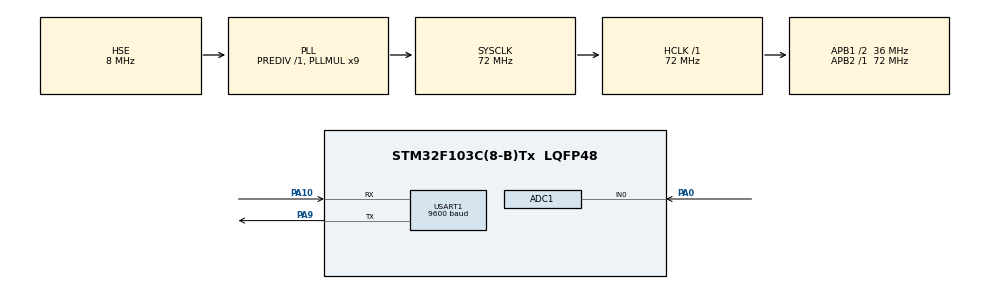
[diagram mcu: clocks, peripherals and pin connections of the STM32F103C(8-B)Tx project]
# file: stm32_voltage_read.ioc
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ADC1.Channel-0\#ChannelRegularConversion=ADC_CHANNEL_0
ADC1.NbrOfConversionFlag=1
ADC1.Rank-0\#ChannelRegularConversion=1
ADC1.SamplingTime-0\#ChannelRegularConversion=ADC_SAMPLETIME_1CYCLE_5
ADC1.master=1
Mcu.Family=STM32F1
Mcu.Name=STM32F103C(8-B)Tx
Mcu.Package=LQFP48
NVIC.PriorityGroup=NVIC_PRIORITYGROUP_4
PA0-WKUP.Signal=ADCx_IN0
PA10.Mode=Asynchronous
PA10.Signal=USART1_RX
PA13.Mode=Serial_Wire
PA13.Signal=SYS_JTMS-SWDIO
PA14.Mode=Serial_Wire
PA14.Signal=SYS_JTCK-SWCLK
PA9.Mode=Asynchronous
PA9.Signal=USART1_TX
PC14-OSC32_IN.Mode=LSE-External-Oscillator
PC14-OSC32_IN.Signal=RCC_OSC32_IN
PC15-OSC32_OUT.Mode=LSE-External-Oscillator
PC15-OSC32_OUT.Signal=RCC_OSC32_OUT
PD0-OSC_IN.Mode=HSE-External-Oscillator
PD0-OSC_IN.Signal=RCC_OSC_IN
PD1-OSC_OUT.Mode=HSE-External-Oscillator
PD1-OSC_OUT.Signal=RCC_OSC_OUT
ProjectManager.HeapSize=0x200
ProjectManager.StackSize=0x400
ProjectManager.TargetToolchain=STM32CubeIDE
RCC.ADCPresc=RCC_ADCPCLK2_DIV6
RCC.AHBFreq_Value=72000000
RCC.APB1CLKDivider=RCC_HCLK_DIV2
RCC.APB1Freq_Value=36000000
RCC.APB1TimFreq_Value=72000000
RCC.APB2Freq_Value=72000000
RCC.APB2TimFreq_Value=72000000
RCC.HCLKFreq_Value=72000000
RCC.PLLMUL=RCC_PLL_MUL9
RCC.PLLSourceVirtual=RCC_PLLSOURCE_HSE
RCC.SYSCLKFreq_VALUE=72000000
RCC.SYSCLKSource=RCC_SYSCLKSOURCE_PLLCLK
RCC.USBFreq_Value=72000000
SH.ADCx_IN0.0=ADC1_IN0,IN0
USART1.BaudRate=9600
USART1.VirtualMode=VM_ASYNC
board=custom

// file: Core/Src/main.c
/* USER CODE BEGIN Header */
/**
  ******************************************************************************
  * @file           : main.c
  * @brief          : Main program body
  ******************************************************************************
  * @attention
  *
  * <h2><center>&copy; Copyright (c) 2021 STMicroelectronics.
  * All rights reserved.</center></h2>
  *
  * This software component is licensed by ST under BSD 3-Clause license,
  * the "License"; You may not use this file except in compliance with the
  * License. You may obtain a copy of the License at:
  *                        opensource.org/licenses/BSD-3-Clause
  *
  ******************************************************************************
  */
/* USER CODE END Header */

#include "main.h"

/* USER CODE BEGIN Includes */
#include <stdio.h>
#include <string.h>
/* USER CODE END Includes */

/* USER CODE BEGIN PTD */

uint16_t raw;
char msg[20];
char msg2[15];
/* USER CODE END PTD */

ADC_HandleTypeDef hadc1;

UART_HandleTypeDef huart1;

void SystemClock_Config(void);
static void MX_GPIO_Init(void);
static void MX_ADC1_Init(void);
static void MX_USART1_UART_Init(void);

int main(void)
{

  /* MCU Configuration--------------------------------------------------------*/

  /* Reset of all peripherals, Initializes the Flash interface and the Systick. */
  HAL_Init();

  /* Configure the system clock */
  SystemClock_Config();

  /* Initialize all configured peripherals */
  MX_GPIO_Init();
  MX_ADC1_Init();
  MX_USART1_UART_Init();

  /* Infinite loop */
  while (1)
  {

	  HAL_ADC_Start(&hadc1);
	  HAL_ADC_PollForConversion(&hadc1, 300);

	  raw =  HAL_ADC_GetValue(&hadc1);
	  float vin = raw*(3.3/4096);
	  sprintf(msg2," vol = %.2f\r\n",vin);
	 HAL_UART_Transmit(&huart1, (uint8_t*)msg2, strlen(msg2), 300);
	 HAL_Delay(5000);

  }
}

void SystemClock_Config(void)
{
  RCC_OscInitTypeDef RCC_OscInitStruct = {0};
  RCC_ClkInitTypeDef RCC_ClkInitStruct = {0};
  RCC_PeriphCLKInitTypeDef PeriphClkInit = {0};

  /** Initializes the CPU, AHB and APB busses clocks
  */
  RCC_OscInitStruct.OscillatorType = RCC_OSCILLATORTYPE_HSE;
  RCC_OscInitStruct.HSEState = RCC_HSE_ON;
  RCC_OscInitStruct.HSEPredivValue = RCC_HSE_PREDIV_DIV1;
  RCC_OscInitStruct.HSIState = RCC_HSI_ON;
  RCC_OscInitStruct.PLL.PLLState = RCC_PLL_ON;
  RCC_OscInitStruct.PLL.PLLSource = RCC_PLLSOURCE_HSE;
  RCC_OscInitStruct.PLL.PLLMUL = RCC_PLL_MUL9;
  if (HAL_RCC_OscConfig(&RCC_OscInitStruct) != HAL_OK)
  {
    Error_Handler();
  }
  /** Initializes the CPU, AHB and APB busses clocks
  */
  RCC_ClkInitStruct.ClockType = RCC_CLOCKTYPE_HCLK|RCC_CLOCKTYPE_SYSCLK
                              |RCC_CLOCKTYPE_PCLK1|RCC_CLOCKTYPE_PCLK2;
  RCC_ClkInitStruct.SYSCLKSource = RCC_SYSCLKSOURCE_PLLCLK;
  RCC_ClkInitStruct.AHBCLKDivider = RCC_SYSCLK_DIV1;
  RCC_ClkInitStruct.APB1CLKDivider = RCC_HCLK_DIV2;
  RCC_ClkInitStruct.APB2CLKDivider = RCC_HCLK_DIV1;

  if (HAL_RCC_ClockConfig(&RCC_ClkInitStruct, FLASH_LATENCY_2) != HAL_OK)
  {
    Error_Handler();
  }
  PeriphClkInit.PeriphClockSelection = RCC_PERIPHCLK_ADC;
  PeriphClkInit.AdcClockSelection = RCC_ADCPCLK2_DIV6;
  if (HAL_RCCEx_PeriphCLKConfig(&PeriphClkInit) != HAL_OK)
  {
    Error_Handler();
  }
}

static void MX_ADC1_Init(void)
{

  ADC_ChannelConfTypeDef sConfig = {0};

  /** Common config
  */
  hadc1.Instance = ADC1;
  hadc1.Init.ScanConvMode = ADC_SCAN_DISABLE;
  hadc1.Init.ContinuousConvMode = DISABLE;
  hadc1.Init.DiscontinuousConvMode = DISABLE;
  hadc1.Init.ExternalTrigConv = ADC_SOFTWARE_START;
  hadc1.Init.DataAlign = ADC_DATAALIGN_RIGHT;
  hadc1.Init.NbrOfConversion = 1;
  if (HAL_ADC_Init(&hadc1) != HAL_OK)
  {
    Error_Handler();
  }
  /** Configure Regular Channel
  */
  sConfig.Channel = ADC_CHANNEL_0;
  sConfig.Rank = ADC_REGULAR_RANK_1;
  sConfig.SamplingTime = ADC_SAMPLETIME_1CYCLE_5;
  if (HAL_ADC_ConfigChannel(&hadc1, &sConfig) != HAL_OK)
  {
    Error_Handler();
  }

}

static void MX_USART1_UART_Init(void)
{

  huart1.Instance = USART1;
  huart1.Init.BaudRate = 9600;
  huart1.Init.WordLength = UART_WORDLENGTH_8B;
  huart1.Init.StopBits = UART_STOPBITS_1;
  huart1.Init.Parity = UART_PARITY_NONE;
  huart1.Init.Mode = UART_MODE_TX_RX;
  huart1.Init.HwFlowCtl = UART_HWCONTROL_NONE;
  huart1.Init.OverSampling = UART_OVERSAMPLING_16;
  if (HAL_UART_Init(&huart1) != HAL_OK)
  {
    Error_Handler();
  }

}

static void MX_GPIO_Init(void)
{

  /* GPIO Ports Clock Enable */
  __HAL_RCC_GPIOC_CLK_ENABLE();
  __HAL_RCC_GPIOD_CLK_ENABLE();
  __HAL_RCC_GPIOA_CLK_ENABLE();

}

void Error_Handler(void)
{
}

/************************ (C) COPYRIGHT STMicroelectronics *****END OF FILE****/
